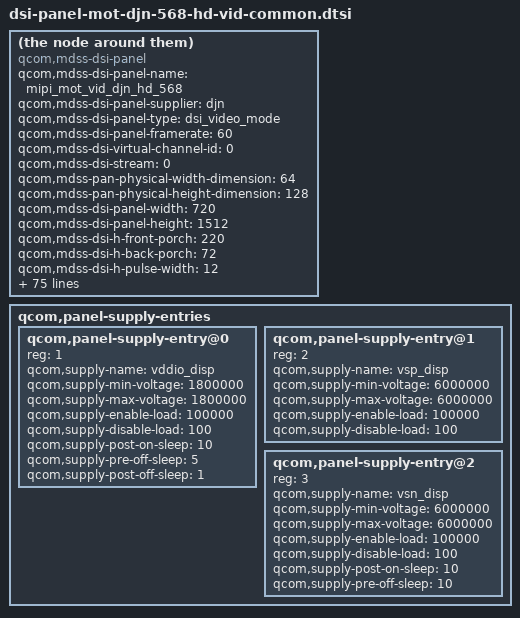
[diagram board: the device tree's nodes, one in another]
/* Copyright (c) 2016, The Linux Foundation. All rights reserved.
 *
 * This program is free software; you can redistribute it and/or modify
 * it under the terms of the GNU General Public License version 2 and
 * only version 2 as published by the Free Software Foundation.
 *
 * This program is distributed in the hope that it will be useful,
 * but WITHOUT ANY WARRANTY; without even the implied warranty of
 * MERCHANTABILITY or FITNESS FOR A PARTICULAR PURPOSE.  See the
 * GNU General Public License for more details.
 */

compatible = "qcom,mdss-dsi-panel";
qcom,mdss-dsi-panel-name = "mipi_mot_vid_djn_hd_568";
qcom,mdss-dsi-panel-supplier = "djn";
qcom,mdss-dsi-panel-type = "dsi_video_mode";
qcom,mdss-dsi-panel-framerate = <60>;
qcom,mdss-dsi-virtual-channel-id = <0>;
qcom,mdss-dsi-stream = <0>;
qcom,mdss-pan-physical-width-dimension = <64>;
qcom,mdss-pan-physical-height-dimension = <128>;
qcom,mdss-dsi-panel-width = <720>;
qcom,mdss-dsi-panel-height = <1512>;
qcom,mdss-dsi-h-front-porch = <220>;
qcom,mdss-dsi-h-back-porch = <72>;
qcom,mdss-dsi-h-pulse-width = <12>;
qcom,mdss-dsi-h-sync-skew = <0>;
qcom,mdss-dsi-v-back-porch = <8>;
qcom,mdss-dsi-v-front-porch = <8>;
qcom,mdss-dsi-v-pulse-width = <2>;
qcom,mdss-dsi-h-left-border = <0>;
qcom,mdss-dsi-h-right-border = <0>;
qcom,mdss-dsi-v-top-border = <0>;
qcom,mdss-dsi-v-bottom-border = <0>;
qcom,mdss-dsi-bpp = <24>;
qcom,mdss-dsi-underflow-color = <0xff>;
qcom,mdss-dsi-border-color = <0>;
qcom,mdss-dsi-on-command = [
			29 01 00 00 00 00 02 FF 23
			29 01 00 00 00 00 02 FB 01
			29 01 00 00 00 00 02 07 20
			29 01 00 00 00 00 02 08 06
			29 01 00 00 00 00 02 09 00
			29 01 00 00 00 00 02 FF 24
			29 01 00 00 00 00 02 FB 01
			29 01 00 00 00 00 02 5E 11
			29 01 00 00 00 00 02 3B 8C
			29 01 00 00 00 00 02 5B 8C
			29 01 00 00 00 00 02 93 08
			29 01 00 00 00 00 02 0A 1C
			29 01 00 00 00 00 02 20 1C
			29 01 00 00 00 00 02 86 00
			29 01 00 00 00 00 02 80 09
			29 01 00 00 00 00 02 81 08
			29 01 00 00 00 00 02 82 09
			29 01 00 00 00 00 02 83 08
			29 01 00 00 00 00 02 84 80
			29 01 00 00 00 00 02 FF 25
			29 01 00 00 00 00 02 FB 01
			29 01 00 00 00 00 02 4C 8C
			29 01 00 00 00 00 02 5E 8C
			29 01 00 00 00 00 02 20 8C
			29 01 00 00 00 00 02 27 8C
			29 01 00 00 00 00 02 34 8C
			29 01 00 00 00 00 02 43 8C
			29 01 00 00 00 00 02 50 8C
			29 01 00 00 00 00 02 62 8C
			29 01 00 00 00 00 02 0A 82
			29 01 00 00 00 00 02 0B 9E
			29 01 00 00 00 00 02 0C 01
			29 01 00 00 00 00 02 FF 26
			29 01 00 00 00 00 02 FB 01
			29 01 00 00 00 00 02 64 8C
			29 01 00 00 00 00 02 83 8C
			29 01 00 00 00 00 02 68 8C
			29 01 00 00 00 00 02 74 8C
			29 01 00 00 00 00 02 7B 8C
			29 01 00 00 00 00 02 87 8C
			29 01 00 00 00 00 02 FF 10
			29 01 00 00 00 00 02 FB 01
			23 01 00 00 00 00 02 51 00
			23 01 00 00 00 00 02 53 24
			23 01 00 00 00 00 02 55 01
			05 01 00 00 00 00 02 29 00
			05 01 00 00 65 00 02 11 00];
qcom,mdss-dsi-off-command = [
			05 01 00 00 14 00 01 28
			05 01 00 00 64 00 01 10];
qcom,mdss-dsi-panel-timings-phy-v2 = [
	20 1d 05 07 03 03 04 a0
	20 1d 05 07 03 03 04 a0
	20 1d 05 07 03 03 04 a0
	20 1d 05 07 03 03 04 a0
	20 11 05 06 03 03 04 a0];
qcom,mdss-dsi-on-command-state = "dsi_lp_mode";
qcom,mdss-dsi-off-command-state = "dsi_lp_mode";

qcom,mdss-dsi-cabc-ui-command = [15 01 00 00 05 00 02 55 01];
qcom,mdss-dsi-cabc-ui-command-state = "dsi_hs_mode";
qcom,mdss-dsi-cabc-mv-command = [15 01 00 00 00 00 02 55 03];
qcom,mdss-dsi-cabc-mv-command-state = "dsi_hs_mode";
qcom,mdss-dsi-cabc-dis-command = [15 01 00 00 00 00 02 55 00];
qcom,mdss-dsi-cabc-dis-command-state = "dsi_hs_mode";
qcom,mdss-dsi-hbm-on-command = [39 01 00 00 00 00 02 51 FF];
qcom,mdss-dsi-hbm-on-command-state = "dsi_hs_mode";
qcom,mdss-dsi-hbm-off-command = [39 01 00 00 00 00 02 51 FF];
qcom,mdss-dsi-hbm-off-command-state = "dsi_hs_mode";
qcom,mdss-dsi-hbm-type = "lcd-dcs-gpio";

qcom,mdss-dsi-h-sync-pulse = <1>;
qcom,mdss-dsi-traffic-mode = "burst_mode";
qcom,mdss-dsi-bllp-eof-power-mode;
qcom,mdss-dsi-bllp-power-mode;
qcom,mdss-dsi-lane-0-state;
qcom,mdss-dsi-lane-1-state;
qcom,mdss-dsi-lane-2-state;
qcom,mdss-dsi-lane-3-state;
qcom,mdss-dsi-t-clk-post = <0x0b>;
qcom,mdss-dsi-t-clk-pre = <0x23>;
qcom,mdss-dsi-bl-min-level = <1>;
qcom,mdss-dsi-bl-max-level = <255>;
qcom,mdss-dsi-dma-trigger = "trigger_sw";
qcom,mdss-dsi-mdp-trigger = "none";
qcom,mdss-dsi-bl-pmic-control-type = "bl_ctrl_dcs";
qcom,mdss-dsi-reset-sequence = <1 10>, <0 10>, <1 5>;
qcom,mdss-dsi-lp11-init;
qcom,mdss-dsi-tx-eot-append;
qcom,mdss-dsi-init-delay-us = <7000>;
qcom,mdss-dsi-lp11-lcdb-reset;
qcom,mdss-panel-off-rst-disable;
qcom,mdss-panel-reset-high;
qcom,esd-check-enabled;
qcom,mdss-dsi-panel-status-command = [06 01 00 01 05 00 01 0A];
qcom,mdss-dsi-panel-status-command-state = "dsi_hs_mode";
qcom,mdss-dsi-panel-status-check-mode = "reg_read";
qcom,mdss-dsi-panel-status-value = <0x9C>;
qcom,mdss-dsi-panel-status-read-length = <1>;
qcom,mdss-dsi-panel-status-valid-params = <1>;
qcom,mdss-dsi-panel-status-command-mode = "dsi_hs_mode";

qcom,panel-supply-entries {
	#address-cells = <1>;
	#size-cells = <0>;

	qcom,panel-supply-entry@0 {
		reg = <1>;
		qcom,supply-name = "vddio_disp";
		qcom,supply-min-voltage = <1800000>;
		qcom,supply-max-voltage = <1800000>;
		qcom,supply-enable-load = <100000>;
		qcom,supply-disable-load = <100>;
		qcom,supply-post-on-sleep = <10>;
		qcom,supply-pre-off-sleep = <5>;
		qcom,supply-post-off-sleep = <1>;
	};

	qcom,panel-supply-entry@1 {
		reg = <2>;
		qcom,supply-name = "vsp_disp";
		qcom,supply-min-voltage = <6000000>;
		qcom,supply-max-voltage = <6000000>;
		qcom,supply-enable-load = <100000>;
		qcom,supply-disable-load = <100>;
	};

	qcom,panel-supply-entry@2 {
		reg = <3>;
		qcom,supply-name = "vsn_disp";
		qcom,supply-min-voltage = <6000000>;
		qcom,supply-max-voltage = <6000000>;
		qcom,supply-enable-load = <100000>;
		qcom,supply-disable-load = <100>;
		qcom,supply-post-on-sleep = <10>;
		qcom,supply-pre-off-sleep = <10>;
	};
};
